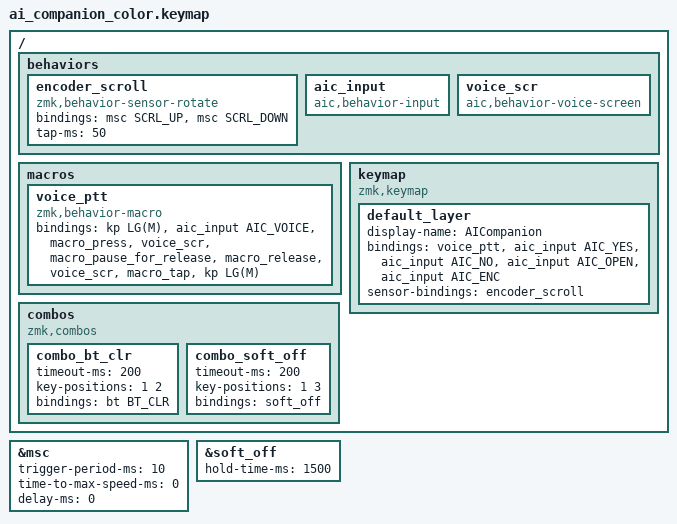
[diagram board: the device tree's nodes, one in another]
/*
 * Copyright (c) 2026 The AI Companion Contributors
 * SPDX-License-Identifier: MIT
 *
 * ai_companion_color keymap — same as the mono `ai_companion` keymap, plus a
 * 5th key: the rotary encoder's push switch (SW), wired on the colour build.
 *
 * Encoder rotation = mouse-wheel scroll (scroll the focused Mac window).
 * The 5 buttons report their press to the Mac as an `input` message over the
 * USB CDC-ACM channel (Phase 5): each is bound to `&aic_input <KEY>` and the
 * host decides what the press means for the screen currently shown.
 *   Voice -> Cmd+M push-to-talk (Optimus mic) + VOICE report,
 *   Yes -> YES,  No -> NO,  Open -> OPEN,  Encoder push -> ENC
 */

#include <behaviors.dtsi>
#include <dt-bindings/zmk/keys.h>
#include <dt-bindings/zmk/bt.h>
#include <dt-bindings/zmk/backlight.h>

/*
 * Physical button ids passed to &aic_input. KEEP IN SYNC with the AIC_KEY_*
 * macros in src/aic_input.h. AIC_ENC (4) is the encoder push switch, present
 * only on this colour build.
 */
#define AIC_VOICE 0
#define AIC_YES   1
#define AIC_NO    2
#define AIC_OPEN  3
#define AIC_ENC   4

#define ZMK_POINTING_DEFAULT_SCRL_VAL 60
#include <dt-bindings/zmk/pointing.h>

/ {
    behaviors {
        // Sensor-rotate behaviour: 1st binding = clockwise, 2nd = counter-clockwise.
        encoder_scroll: encoder_scroll {
            compatible = "zmk,behavior-sensor-rotate";
            #sensor-binding-cells = <0>;
            bindings = <&msc SCRL_UP>, <&msc SCRL_DOWN>;
            tap-ms = <50>;
        };

        // Physical-button behaviour: on press, report which button to the host.
        // Implemented in src/behavior_input.c (compatible "aic,behavior-input").
        aic_input: aic_input {
            compatible = "aic,behavior-input";
            #binding-cells = <1>;
        };

        // Local Voice "listening" screen: pressed() shows LISTENING, released()
        // restores the previous screen. Driven by voice_ptt via macro_press /
        // macro_release so it tracks the physical hold (src/behavior_voice_screen.c).
        voice_scr: voice_scr {
            compatible = "aic,behavior-voice-screen";
            #binding-cells = <0>;
        };
    };
};

&msc {
    trigger-period-ms = <10>;
    time-to-max-speed-ms = <0>;
    delay-ms = <0>;
};

/ {
    macros {
        /*
         * Voice = push-to-talk for Optimus. Optimus's "Voice input" is the
         * keyboard shortcut Cmd+M, a TOGGLE (1st press starts listening, 2nd
         * stops). To get a hold-to-talk feel we tap Cmd+M on PRESS (start) and
         * tap Cmd+M again on RELEASE (stop) — so holding Voice records and
         * letting go stops/sends. Also report VOICE to the host on press, so a
         * running bridge can still drive the LISTENING screen.
         *
         * voice_scr is wrapped in &macro_press / &macro_release around
         * &macro_pause_for_release, so the device shows its OWN local LISTENING
         * screen for exactly as long as the button is held — even with no host
         * running — and reverts the moment you let go.
         *
         * GOTCHA: &macro_release makes the macro's press/release mode sticky for
         * every following binding, so the final Cmd+M MUST be &macro_tap'd back
         * to tap mode — otherwise it only emits a key-release (no press) and
         * Optimus's mic never toggles off (you'd have to press Voice again).
         *
         * NOTE: Cmd+M is delivered to the FRONTMOST app, so Optimus must be
         * focused for this to open its mic; otherwise Cmd+M just minimises
         * whatever window is in front.
         */
        voice_ptt: voice_ptt {
            compatible = "zmk,behavior-macro";
            #binding-cells = <0>;
            bindings
                = <&kp LG(M)>
                , <&aic_input AIC_VOICE>
                , <&macro_press &voice_scr>
                , <&macro_pause_for_release>
                , <&macro_release &voice_scr>
                , <&macro_tap &kp LG(M)>;
        };
    };
};

/ {
    keymap {
        compatible = "zmk,keymap";

        default_layer {
            display-name = "AICompanion";
            bindings = <
                &voice_ptt   &aic_input AIC_YES   &aic_input AIC_NO   &aic_input AIC_OPEN   &aic_input AIC_ENC
            >;
            sensor-bindings = <&encoder_scroll>;
        };
    };
};

/ {
    /*
     * Yes (pos 1) + No (pos 2) pressed together -> clear the active BLE
     * profile's bond. Lets any unit re-pair / recover from a stale bond
     * without a reflash. Pressing Yes or No alone still reports normally.
     *
     * Yes (pos 1) + Open (pos 3) HELD ~1.5s -> &soft_off (真·關機). The device
     * powers into nRF52840 System OFF (~µA); press ANY key to wake it back up
     * (kscan0 is the soft-off wakeup source — see the .overlay). The ~1.5s hold
     * (hold-time-ms override below) stops a brief accidental Yes+Open tap from
     * shutting the device down; a quick tap does nothing. Does not collide with
     * the Yes+No BT_CLR combo (different key pair).
     */
    combos {
        compatible = "zmk,combos";

        combo_bt_clr {
            timeout-ms = <200>;
            key-positions = <1 2>;
            bindings = <&bt BT_CLR>;
        };

        combo_soft_off {
            timeout-ms = <200>;
            key-positions = <1 3>;
            bindings = <&soft_off>;
        };
    };
};

/*
 * Require the Yes+Open combo to be HELD ~1.5s before it actually powers off
 * (default &soft_off fires the instant the key is released, even on a tap).
 */
&soft_off {
    hold-time-ms = <1500>;
};
